# MKE15D7 register map
File version: 1.6
Registers are 32-bit, read-write, reset 0x0 unless marked. A register's access mark holds for its fields unless they carry their own. Offsets are from the block's base; [hi:lo] are bit positions; {n}, {i} and the like mark numbered series; 'fields as' and 'values as' point back to an identical list.

## PTA — General Purpose Input/Output
Base 0x4007F000; register names take the prefix GPIOA_
0x00 PDOR — Port Data Output Register
  [31:0] PDO — Port Data Output
    0=Logic level 0 is driven on pin, provided pin is configured for general-purpose output; 1=Logic level 1 is driven on pin, provided pin is configured for general-purpose output
0x04 PSOR wo — Port Set Output Register
  [31:0] PTSO — Port Set Output
    0=Corresponding bit in PDORn does not change; 1=Corresponding bit in PDORn is set to logic 1
0x08 PCOR wo — Port Clear Output Register
  [31:0] PTCO — Port Clear Output
    0=Corresponding bit in PDORn does not change; 1=Corresponding bit in PDORn is cleared to logic 0
0x0C PTOR wo — Port Toggle Output Register
  [31:0] PTTO — Port Toggle Output
    0=Corresponding bit in PDORn does not change; 1=Corresponding bit in PDORn is set to the inverse of its existing logic state
0x10 PDIR ro — Port Data Input Register
  [31:0] PDI — Port Data Input
    0=Pin logic level is logic 0, or is not configured for use by digital function; 1=Pin logic level is logic 1
0x14 PDDR — Port Data Direction Register
  [31:0] PDD — Port Data Direction
    0=Pin is configured as general-purpose input, for the GPIO function; 1=Pin is configured as general-purpose output, for the GPIO function

## PTB — General Purpose Input/Output
Base 0x4007F040; register names take the prefix GPIOB_
Registers as PTA.

## PTC — General Purpose Input/Output
Base 0x4007F080; register names take the prefix GPIOC_
Registers as PTA; these are added or differ:
0x08 PCOR wo — Port Clear Output Register
  [31:0] PTCO — Port Clear Output
    0=Corresponding bit in PDORn does not change; 1=Corresponding bit in PDORn is cleared to logic 0

## PTD — General Purpose Input/Output
Base 0x4007F0C0; register names take the prefix GPIOD_
Registers as PTA.

## PTE — General Purpose Input/Output
Base 0x4007F100; register names take the prefix GPIOE_
Registers as PTA.

## SysTick — System timer
Base 0xE000E010; register names take the prefix SYST_
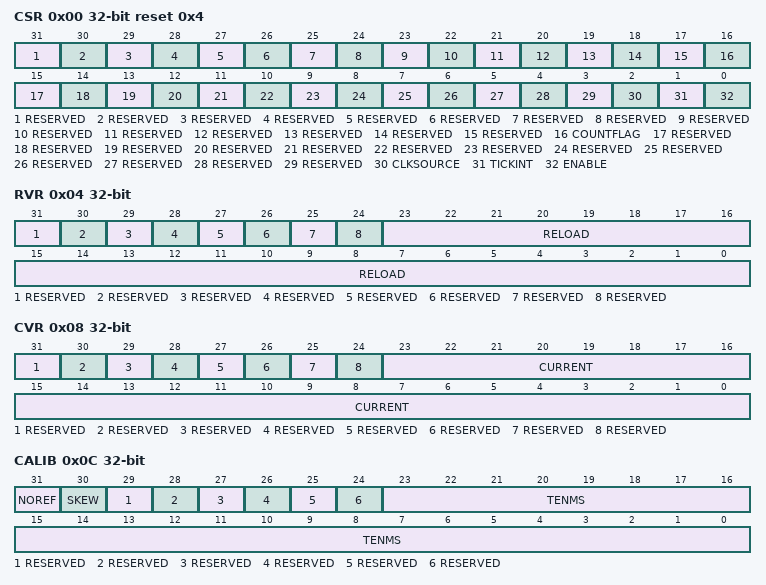
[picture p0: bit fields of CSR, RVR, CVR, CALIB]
0x00 CSR reset 0x4 — SysTick Control and Status Register
  [31] RESERVED ro
  [30] RESERVED ro
  [29] RESERVED ro
  [28] RESERVED ro
  [27] RESERVED ro
  [26] RESERVED ro
  [25] RESERVED ro
  [24] RESERVED ro
  [23] RESERVED ro
  [22] RESERVED ro
  [21] RESERVED ro
  [20] RESERVED ro
  [19] RESERVED ro
  [18] RESERVED ro
  [17] RESERVED ro
  [16] COUNTFLAG
  [15] RESERVED ro
  [14] RESERVED ro
  [13] RESERVED ro
  [12] RESERVED ro
  [11] RESERVED ro
  [10] RESERVED ro
  [9] RESERVED ro
  [8] RESERVED ro
  [7] RESERVED ro
  [6] RESERVED ro
  [5] RESERVED ro
  [4] RESERVED ro
  [3] RESERVED ro
  [2] CLKSOURCE
    0=external clock; 1=processor clock
  [1] TICKINT
    0=counting down to 0 does not assert the SysTick exception request; 1=counting down to 0 asserts the SysTick exception request
  [0] ENABLE
    0=counter disabled; 1=counter enabled
0x04 RVR — SysTick Reload Value Register
  [31] RESERVED ro
  [30] RESERVED ro
  [29] RESERVED ro
  [28] RESERVED ro
  [27] RESERVED ro
  [26] RESERVED ro
  [25] RESERVED ro
  [24] RESERVED ro
  [23:0] RELOAD — Value to load into the SysTick Current Value Register when the counter reaches 0
0x08 CVR — SysTick Current Value Register
  [31] RESERVED ro
  [30] RESERVED ro
  [29] RESERVED ro
  [28] RESERVED ro
  [27] RESERVED ro
  [26] RESERVED ro
  [25] RESERVED ro
  [24] RESERVED ro
  [23:0] CURRENT — Current value at the time the register is accessed
0x0C CALIB ro — SysTick Calibration Value Register
  [31] NOREF
    0=The reference clock is provided; 1=The reference clock is not provided
  [30] SKEW
    0=10ms calibration value is exact; 1=10ms calibration value is inexact, because of the clock frequency
  [29] RESERVED
  [28] RESERVED
  [27] RESERVED
  [26] RESERVED
  [25] RESERVED
  [24] RESERVED
  [23:0] TENMS — Reload value to use for 10ms timing

## NVIC — Nested Vectored Interrupt Controller
Base 0xE000E100
{0x0+4i} NVICISER{i} (i=0..3) — Interrupt Set Enable Register n
  [31:0] SETENA — Interrupt set enable bits
{0x80+4i} NVICICER{i} (i=0..3) — Interrupt Clear Enable Register n
  [31:0] CLRENA — Interrupt clear-enable bits
{0x100+4i} NVICISPR{i} (i=0..3) — Interrupt Set Pending Register n
  [31:0] SETPEND — Interrupt set-pending bits
{0x180+4i} NVICICPR{i} (i=0..3) — Interrupt Clear Pending Register n
  [31:0] CLRPEND — Interrupt clear-pending bits
{0x200+4i} NVICIABR{i} (i=0..3) — Interrupt Active bit Register n
  [31:0] ACTIVE — Interrupt active flags
{0x300+i} NVICIP{i} 8-bit (i=0..105) — Interrupt Priority Register n
  [7:0] PRI{i} — Priority of interrupt {i}
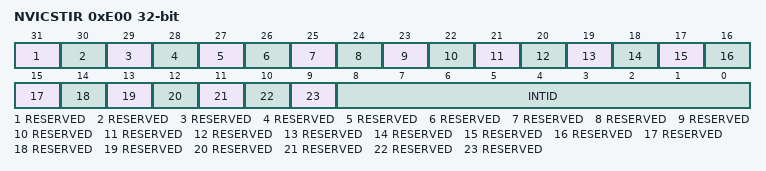
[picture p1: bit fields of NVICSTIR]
0xE00 NVICSTIR — Software Trigger Interrupt Register
  [31] RESERVED
  [30] RESERVED
  [29] RESERVED
  [28] RESERVED
  [27] RESERVED
  [26] RESERVED
  [25] RESERVED
  [24] RESERVED
  [23] RESERVED
  [22] RESERVED
  [21] RESERVED
  [20] RESERVED
  [19] RESERVED
  [18] RESERVED
  [17] RESERVED
  [16] RESERVED
  [15] RESERVED
  [14] RESERVED
  [13] RESERVED
  [12] RESERVED
  [11] RESERVED
  [10] RESERVED
  [9] RESERVED
  [8:0] INTID — Interrupt ID of the interrupt to trigger, in the range 0-239. For example, a value of 0x03 specifies interrupt IRQ3.

## MCM — Core Platform Miscellaneous Control Module
Base 0xE0080000; register names take the prefix MCM_
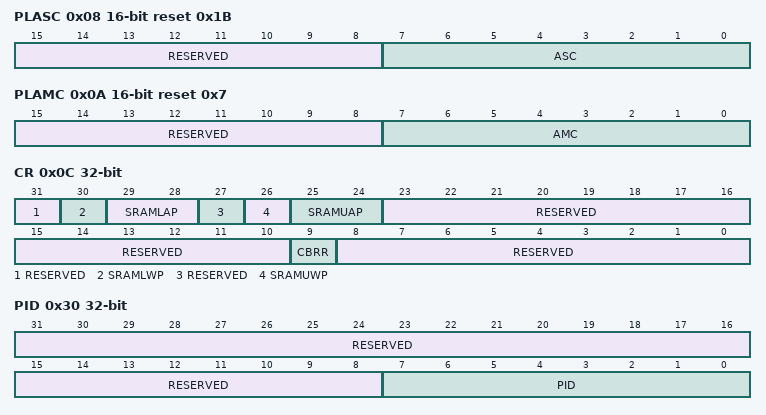
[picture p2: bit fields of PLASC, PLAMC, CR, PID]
0x08 PLASC 16-bit ro reset 0x1B — Crossbar Switch (AXBS) Slave Configuration
  [15:8] RESERVED
  [7:0] ASC — Each bit in the ASC field indicates whether there is a corresponding connection to the crossbar switch's slave input port.
    0=A bus slave connection to AXBS input port n is absent; 1=A bus slave connection to AXBS input port n is present
0x0A PLAMC 16-bit ro reset 0x7 — Crossbar Switch (AXBS) Master Configuration
  [15:8] RESERVED
  [7:0] AMC — Each bit in the AMC field indicates whether there is a corresponding connection to the AXBS master input port.
    0=A bus master connection to AXBS input port n is absent; 1=A bus master connection to AXBS input port n is present
0x0C CR — Control Register
  [31] RESERVED ro
  [30] SRAMLWP — SRAM_L Write Protect
  [29:28] SRAMLAP — SRAM_L arbitration priority
    0=Round robin; 1=Special round robin (favors SRAM backoor accesses over the processor); 2=Fixed priority. Processor has highest, backdoor has lowest; 3=Fixed priority. Backdoor has highest, processor has lowest
  [27] RESERVED ro
  [26] SRAMUWP — SRAM_U write protect
  [25:24] SRAMUAP — SRAM_U arbitration priority
    values as SRAMLAP
  [23:10] RESERVED ro
  [9] CBRR ro — Crossbar round-robin arbitration enable
    0=Fixed-priority arbitration; 1=Round-robin arbitration
  [8:0] RESERVED ro
0x30 PID — Process ID register
  [31:8] RESERVED ro
  [7:0] PID — M0_PID And M1_PID For MPU
